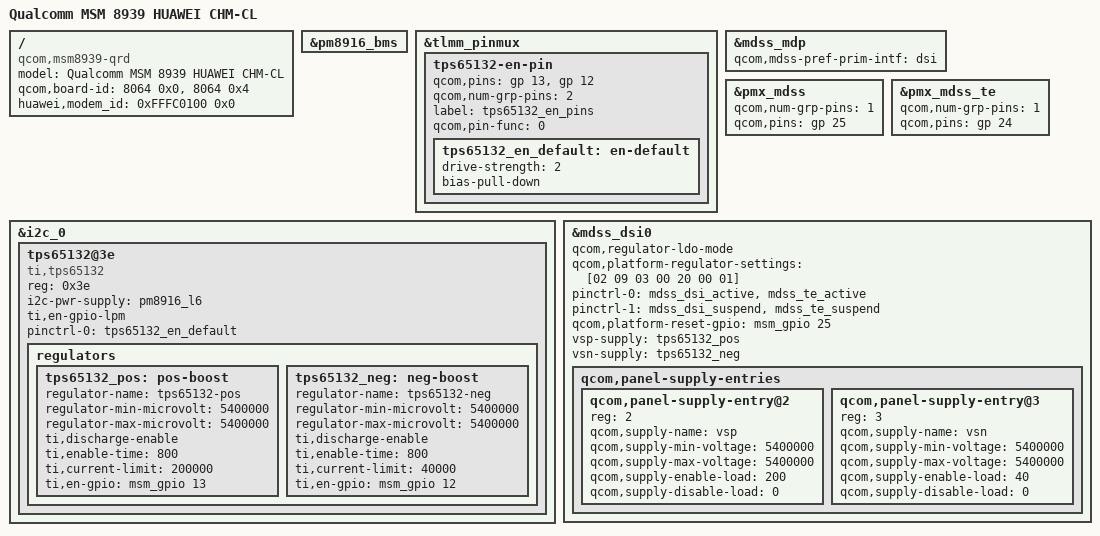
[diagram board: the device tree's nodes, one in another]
/* Copyright (c) 2014, The Linux Foundation. All rights reserved.
 *
 * This program is free software; you can redistribute it and/or modify
 * it under the terms of the GNU General Public License version 2 and
 * only version 2 as published by the Free Software Foundation.
 *
 * This program is distributed in the hope that it will be useful,
 * but WITHOUT ANY WARRANTY; without even the implied warranty of
 * MERCHANTABILITY or FITNESS FOR A PARTICULAR PURPOSE.  See the
 * GNU General Public License for more details.
 */
/dts-v1/;
#include "msm8939.dtsi"
#include "msm8939-qrd.dtsi"
#include "huawei_msm8939_chm_cl_vb/huawei.dtsi"
/ {
	model = "Qualcomm MSM 8939 HUAWEI CHM-CL";
	compatible = "qcom,msm8939-qrd", "qcom,msm8939", "qcom,qrd";
	qcom,board-id = <8064 0x0> , <8064 0x4>;/*1G*/
	huawei,modem_id = <0xFFFC0100 0x0>;
};

&pm8916_bms {
	status = "ok";
};

&tlmm_pinmux {

	tps65132-en-pin {
		qcom,pins = <&gp 13>, <&gp 12>;
		qcom,num-grp-pins = <2>;
		label = "tps65132_en_pins";
		qcom,pin-func = <0>;

		tps65132_en_default: en-default {
			drive-strength = <2>;
			bias-pull-down;
		};
	};
};

&i2c_0 { /* BLSP1 QUP2 */
	tps65132@3e {
		compatible = "ti,tps65132";
		reg = <0x3e>;
		i2c-pwr-supply = <&pm8916_l6>;
		ti,en-gpio-lpm;
		pinctrl-names = "default";
		pinctrl-0 = <&tps65132_en_default>;

		regulators {
			tps65132_pos: pos-boost {
				regulator-name = "tps65132-pos";
				regulator-min-microvolt = <5400000>;
				regulator-max-microvolt = <5400000>;
				ti,discharge-enable;
				ti,enable-time = <800>;
				ti,current-limit = <200000>;
				ti,en-gpio = <&msm_gpio 13 0>;
			};

			tps65132_neg: neg-boost {
				regulator-name = "tps65132-neg";
				regulator-min-microvolt = <5400000>;
				regulator-max-microvolt = <5400000>;
				ti,discharge-enable;
				ti,enable-time = <800>;
				ti,current-limit = <40000>;
				ti,en-gpio = <&msm_gpio 12 0>;
			};
		};
	};
};

&mdss_mdp {
	qcom,mdss-pref-prim-intf = "dsi";
};

&pmx_mdss {
	qcom,num-grp-pins = <1>;
	qcom,pins = <&gp 25>;
};

&pmx_mdss_te {
	qcom,num-grp-pins = <1>;
	qcom,pins = <&gp 24>;
};

&mdss_dsi0 {
	qcom,regulator-ldo-mode;
	qcom,platform-regulator-settings = [02 09 03 00 20 00 01];
	pinctrl-names = "mdss_default", "mdss_sleep";
	pinctrl-0 = <&mdss_dsi_active &mdss_te_active>;
	pinctrl-1 = <&mdss_dsi_suspend &mdss_te_suspend>;

	qcom,platform-reset-gpio = <&msm_gpio 25 0>;

	vsp-supply = <&tps65132_pos>;
	vsn-supply = <&tps65132_neg>;

	qcom,panel-supply-entries {
		#address-cells = <1>;
		#size-cells = <0>;

		qcom,panel-supply-entry@2 {
			reg = <2>;
			qcom,supply-name = "vsp";
			qcom,supply-min-voltage = <5400000>;
			qcom,supply-max-voltage = <5400000>;
			qcom,supply-enable-load = <200>;
			qcom,supply-disable-load = <0>;
		};

		qcom,panel-supply-entry@3 {
			reg = <3>;
			qcom,supply-name = "vsn";
			qcom,supply-min-voltage = <5400000>;
			qcom,supply-max-voltage = <5400000>;
			qcom,supply-enable-load = <40>;
			qcom,supply-disable-load = <0>;
		};
	};

};
